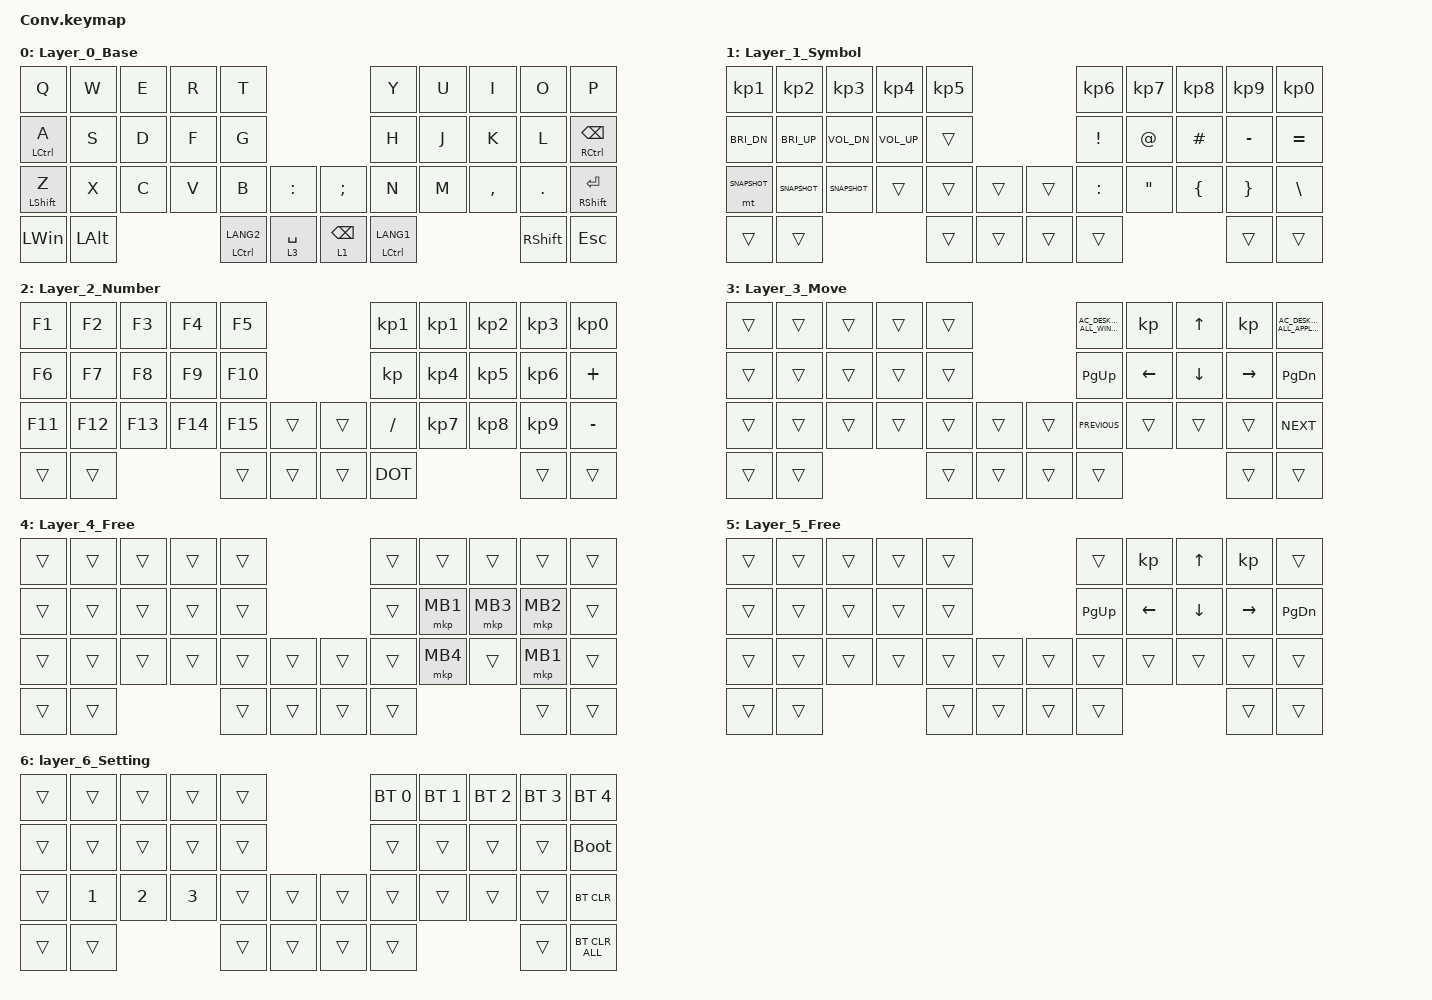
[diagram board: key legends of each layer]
#include <behaviors.dtsi>
#include <dt-bindings/zmk/bt.h>
#include <dt-bindings/zmk/keys.h>
#include <dt-bindings/zmk/pointing.h>
#include <input/processors.dtsi>

#define MOUSE 4
#define SCROLL 5
#define NUM 6

&mkp_input_listener {
    input-processors = <&zip_temp_layer 2 250>
};

&mt {
    flavor = "balanced";
    quick-tap-ms = <0>;
};

/ {
    combos {
        compatible = "zmk,combos";

        tab {
            bindings = <&kp TAB>;
            key-positions = <11 12>;
        };

        shift_tab {
            bindings = <&kp LS(TAB)>;
            key-positions = <12 13>;
        };

        muhennkann {
            bindings = <&to_layer_0 INT_MUHENKAN>;
            key-positions = <11 10>;
        };

        double_quotation {
            bindings = <&kp DOUBLE_QUOTES>;
            key-positions = <20 21>;
        };

        eq {
            bindings = <&kp EQUAL>;
            key-positions = <24 25>;
        };
    };

    macros {
        to_layer_0: to_layer_0 {
            compatible = "zmk,behavior-macro-one-param";
            #binding-cells = <1>;
            bindings = <&to 0 &macro_param_1to1 &kp MACRO_PLACEHOLDER>;
            label = "TO_LAYER_0";
        };
    };

    behaviors {
        lt_to_layer_0: lt_to_layer_0 {
            compatible = "zmk,behavior-hold-tap";
            label = "LAYER_TAP_TO_0";
            bindings = <&mo>, <&to_layer_0>;

            #binding-cells = <2>;
            tapping-term-ms = <200>;
        };
    };

    keymap {
        compatible = "zmk,keymap";

        Layer_0_Base {
            bindings = <
&kp Q            &kp W        &kp E &kp R &kp T                                                     &kp Y           &kp U  &kp I     &kp O           &kp P
&mt LCTRL A      &kp S        &kp D &kp F &kp G                                                     &kp H           &kp J  &kp K     &kp L           &mt RCTRL BACKSPACE
&mt LEFT_SHIFT Z &kp X        &kp C &kp V &kp B            &kp COLON                &kp SEMICOLON   &kp N           &kp M  &kp COMMA &kp DOT         &mt RIGHT_SHIFT ENTER
&kp LEFT_WIN     &kp LEFT_ALT             &mt LCTRL LANG2  &lt 3 SPACE              &lt 1 BACKSPACE &mt LCTRL LANG1                  &kp RIGHT_SHIFT &kp ESC
            >;

            sensor-bindings = <&inc_dec_kp PG_UP PAGE_DOWN>;
        };


    Layer_1_Symbol {
            bindings = <
&kp KP_NUMBER_1 &kp KP_NUMBER_2 &kp KP_NUMBER_3 &kp KP_NUMBER_4 &kp KP_NUMBER_5                                   &kp KP_NUMBER_6 &kp KP_NUMBER_7 &kp KP_NUMBER_8 &kp KP_NUMBER_9 &kp KP_NUMBER_0
&kp C_BRI_DN    &kp C_BRI_UP    &kp C_VOL_DN    &kp C_VOL_UP    &trans                                            &kp EXCLAMATION &kp AT_SIGN     &kp HASH        &kp MINUS       &kp EQUAL
&mt C_SNAPSHOT  &kp C_SNAPSHOT  &kp C_SNAPSHOT  &trans          &trans        &trans                       &trans &kp COLON       &kp DQT         &kp LEFT_BRACE  &kp RIGHT_BRACE &kp BSLH
&trans          &trans                                          &trans        &trans                       &trans &trans                                          &trans          &trans
            >;
        };

    Layer_2_Number {
            bindings = <
&kp F1  &kp F2  &kp F3  &kp F4  &kp F5                               &kp KP_NUMBER_1 &kp KP_NUMBER_1 &kp KP_NUMBER_2 &kp KP_NUMBER_3 &kp KP_NUMBER_0
&kp F6  &kp F7  &kp F8  &kp F9  &kp F10                              &kp             &kp KP_NUMBER_4 &kp KP_NUMBER_5 &kp KP_NUMBER_6 &kp PLUS   
&kp F11 &kp F12 &kp F13 &kp F14 &kp F15 &trans                &trans &kp SLASH       &kp KP_NUMBER_7 &kp KP_NUMBER_8 &kp KP_NUMBER_9 &kp MINUS
&trans  &trans                  &trans  &trans                &trans &DOT                                            &trans          &trans
            >;
        };


    Layer_3_Move {
            bindings = <
&trans  &trans  &trans  &trans  &trans                      &kp C_AC_DESKTOP_SHOW_ALL_WINDOWS &kp      &kp UP   &kp       &kp C_AC_DESKTOP_SHOW_ALL_APPLICATIONS
&trans  &trans  &trans  &trans  &trans                      &kp PAGE_UP                       &kp LEFT &kp DOWN &kp RIGHT &kp PAGE_DOWN
&trans  &trans  &trans  &trans  &trans  &trans      &trans  &kp C_PREVIOUS                    &trans   &trans   &trans    &kp C_NEXT
&trans  &trans                  &trans  &trans      &trans  &trans                                              &trans    &trans
            >;

            sensor-bindings = <&inc_dec_kp LC(PAGE_UP) LC(PAGE_DOWN)>;
        };

    Layer_4_Free {
            bindings = <
&trans  &trans  &trans  &trans  &trans                      &trans  &trans   &trans   &trans   &trans
&trans  &trans  &trans  &trans  &trans                      &trans  &mkp MB1 &mkp MB3 &mkp MB2 &trans
&trans  &trans  &trans  &trans  &trans  &trans      &trans  &trans  &mkp MB4 &trans   &mkp MB1 &trans
&trans  &trans                  &trans  &trans      &trans  &trans                    &trans   &trans
            >;
        };

    Layer_5_Free {
            bindings = <
&trans  &trans  &trans  &trans  &trans                      &trans      &kp      &kp UP   &kp       &trans
&trans  &trans  &trans  &trans  &trans                      &kp PAGE_UP &kp LEFT &kp DOWN &kp RIGHT &kp PAGE_DOWN
&trans  &trans  &trans  &trans  &trans  &trans      &trans  &trans      &trans   &trans   &trans    &trans
&trans  &trans                  &trans  &trans      &trans  &trans                        &trans    &trans
            >;
        };

    layer_6_Setting {
            bindings = <
&trans  &trans        &trans        &trans        &trans                           &bt BT_SEL 0  &bt BT_SEL 1  &bt BT_SEL 2  &bt BT_SEL 3  &bt BT_SEL 4
&trans  &trans        &trans        &trans        &trans                           &trans        &trans        &trans        &trans        &bootloader
&trans  &kp NUMBER_1  &kp NUMBER_2  &kp NUMBER_3  &trans  &trans      &trans       &trans        &trans        &trans        &trans        &bt BT_CLR
&trans  &trans                                    &trans  &trans      &trans       &trans                                    &trans        &bt BT_CLR_ALL
            >;
        };
    };
};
